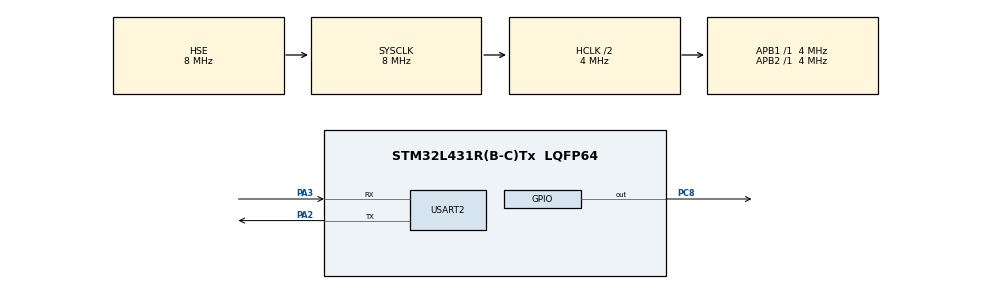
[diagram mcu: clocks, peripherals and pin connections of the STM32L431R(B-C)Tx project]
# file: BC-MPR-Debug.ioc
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Mcu.Family=STM32L4
Mcu.Name=STM32L431R(B-C)Tx
Mcu.Package=LQFP64
NVIC.PriorityGroup=NVIC_PRIORITYGROUP_4
PA13\ (JTMS-SWDIO).Mode=JTAG_5_pins
PA13\ (JTMS-SWDIO).Signal=SYS_JTMS-SWDIO
PA14\ (JTCK-SWCLK).Mode=JTAG_5_pins
PA14\ (JTCK-SWCLK).Signal=SYS_JTCK-SWCLK
PA15\ (JTDI).Mode=JTAG_5_pins
PA15\ (JTDI).Signal=SYS_JTDI
PA2.Mode=Asynchronous
PA2.Signal=USART2_TX
PA3.Mode=Asynchronous
PA3.Signal=USART2_RX
PB3\ (JTDO-TRACESWO).Mode=JTAG_5_pins
PB3\ (JTDO-TRACESWO).Signal=SYS_JTDO-SWO
PB4\ (NJTRST).Mode=JTAG_5_pins
PB4\ (NJTRST).Signal=SYS_JTRST
PC14-OSC32_IN\ (PC14).Mode=LSE-External-Oscillator
PC14-OSC32_IN\ (PC14).Signal=RCC_OSC32_IN
PC15-OSC32_OUT\ (PC15).Mode=LSE-External-Oscillator
PC15-OSC32_OUT\ (PC15).Signal=RCC_OSC32_OUT
PC8.Signal=GPIO_Output
PH0-OSC_IN\ (PH0).Mode=HSE-External-Oscillator
PH0-OSC_IN\ (PH0).Signal=RCC_OSC_IN
PH1-OSC_OUT\ (PH1).Mode=HSE-External-Oscillator
PH1-OSC_OUT\ (PH1).Signal=RCC_OSC_OUT
ProjectManager.HeapSize=0x200
ProjectManager.StackSize=0x400
ProjectManager.TargetToolchain=STM32CubeIDE
RCC.ADCFreq_Value=32000000
RCC.AHBCLKDivider=RCC_SYSCLK_DIV2
RCC.AHBFreq_Value=4000000
RCC.APB1Freq_Value=4000000
RCC.APB1TimFreq_Value=4000000
RCC.APB2Freq_Value=4000000
RCC.APB2TimFreq_Value=4000000
RCC.CortexFreq_Value=4000000
RCC.HCLKFreq_Value=4000000
RCC.HSE_VALUE=8000000
RCC.HSI48_VALUE=48000000
RCC.HSI_VALUE=16000000
RCC.MSI_VALUE=4000000
RCC.PLLSourceVirtual=RCC_PLLSOURCE_HSE
RCC.SYSCLKFreq_VALUE=8000000
RCC.SYSCLKSource=RCC_SYSCLKSOURCE_HSE
RCC.VCOOutputFreq_Value=64000000
USART2.VirtualMode-Asynchronous=VM_ASYNC
board=custom

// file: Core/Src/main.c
/* USER CODE BEGIN Header */
/**
  ******************************************************************************
  * @file           : main.c
  * @brief          : Main program body
  ******************************************************************************
  * @attention
  *
  * Copyright (c) 2025 STMicroelectronics.
  * All rights reserved.
  *
  * This software is licensed under terms that can be found in the LICENSE file
  * in the root directory of this software component.
  * If no LICENSE file comes with this software, it is provided AS-IS.
  *
  ******************************************************************************
  */
/* USER CODE END Header */
#include "main.h"

UART_HandleTypeDef huart2;

void SystemClock_Config(void);
static void MX_GPIO_Init(void);
static void MX_USART2_UART_Init(void);

int main(void)
{

  /* MCU Configuration--------------------------------------------------------*/

  /* Reset of all peripherals, Initializes the Flash interface and the Systick. */
  HAL_Init();

  /* Configure the system clock */
  SystemClock_Config();

  /* Initialize all configured peripherals */
  MX_GPIO_Init();
  MX_USART2_UART_Init();

  /* Infinite loop */
  /* USER CODE BEGIN WHILE */
  while (1)
  {
	  // Toggle heartbeat LED every half second
	  HAL_Delay(500);
	  HAL_GPIO_TogglePin(GPIOC, GPIO_PIN_8);
    /* USER CODE END WHILE */

  }
}

void SystemClock_Config(void)
{
  RCC_OscInitTypeDef RCC_OscInitStruct = {0};
  RCC_ClkInitTypeDef RCC_ClkInitStruct = {0};

  /** Configure the main internal regulator output voltage
  */
  if (HAL_PWREx_ControlVoltageScaling(PWR_REGULATOR_VOLTAGE_SCALE1) != HAL_OK)
  {
    Error_Handler();
  }

  /** Initializes the RCC Oscillators according to the specified parameters
  * in the RCC_OscInitTypeDef structure.
  */
  RCC_OscInitStruct.OscillatorType = RCC_OSCILLATORTYPE_HSE;
  RCC_OscInitStruct.HSEState = RCC_HSE_ON;
  RCC_OscInitStruct.PLL.PLLState = RCC_PLL_NONE;
  if (HAL_RCC_OscConfig(&RCC_OscInitStruct) != HAL_OK)
  {
    Error_Handler();
  }

  /** Initializes the CPU, AHB and APB buses clocks
  */
  RCC_ClkInitStruct.ClockType = RCC_CLOCKTYPE_HCLK|RCC_CLOCKTYPE_SYSCLK
                              |RCC_CLOCKTYPE_PCLK1|RCC_CLOCKTYPE_PCLK2;
  RCC_ClkInitStruct.SYSCLKSource = RCC_SYSCLKSOURCE_HSE;
  RCC_ClkInitStruct.AHBCLKDivider = RCC_SYSCLK_DIV2;
  RCC_ClkInitStruct.APB1CLKDivider = RCC_HCLK_DIV1;
  RCC_ClkInitStruct.APB2CLKDivider = RCC_HCLK_DIV1;

  if (HAL_RCC_ClockConfig(&RCC_ClkInitStruct, FLASH_LATENCY_0) != HAL_OK)
  {
    Error_Handler();
  }
}

static void MX_USART2_UART_Init(void)
{

  huart2.Instance = USART2;
  huart2.Init.BaudRate = 115200;
  huart2.Init.WordLength = UART_WORDLENGTH_8B;
  huart2.Init.StopBits = UART_STOPBITS_1;
  huart2.Init.Parity = UART_PARITY_NONE;
  huart2.Init.Mode = UART_MODE_TX_RX;
  huart2.Init.HwFlowCtl = UART_HWCONTROL_NONE;
  huart2.Init.OverSampling = UART_OVERSAMPLING_16;
  huart2.Init.OneBitSampling = UART_ONE_BIT_SAMPLE_DISABLE;
  huart2.AdvancedInit.AdvFeatureInit = UART_ADVFEATURE_NO_INIT;
  if (HAL_UART_Init(&huart2) != HAL_OK)
  {
    Error_Handler();
  }

}

static void MX_GPIO_Init(void)
{
  GPIO_InitTypeDef GPIO_InitStruct = {0};

  /* GPIO Ports Clock Enable */
  __HAL_RCC_GPIOC_CLK_ENABLE();
  __HAL_RCC_GPIOH_CLK_ENABLE();
  __HAL_RCC_GPIOA_CLK_ENABLE();
  __HAL_RCC_GPIOB_CLK_ENABLE();

  /*Configure GPIO pin Output Level */
  HAL_GPIO_WritePin(GPIOC, GPIO_PIN_8, GPIO_PIN_RESET);

  /*Configure GPIO pin : PC8 */
  GPIO_InitStruct.Pin = GPIO_PIN_8;
  GPIO_InitStruct.Mode = GPIO_MODE_OUTPUT_PP;
  GPIO_InitStruct.Pull = GPIO_NOPULL;
  GPIO_InitStruct.Speed = GPIO_SPEED_FREQ_LOW;
  HAL_GPIO_Init(GPIOC, &GPIO_InitStruct);

}

void Error_Handler(void)
{
  __disable_irq();
  while (1)
  {
  }
}
